# M460 register map
File version: 1.0
Registers are 32-bit, read-write, reset 0x0 unless marked. A register's access mark holds for its fields unless they carry their own. Offsets are from the block's base; [hi:lo] are bit positions; {n}, {i} and the like mark numbered series; 'fields as' and 'values as' point back to an identical list.

## CLK (part 1 of 2) — CLK Register Map
Base 0x40000200
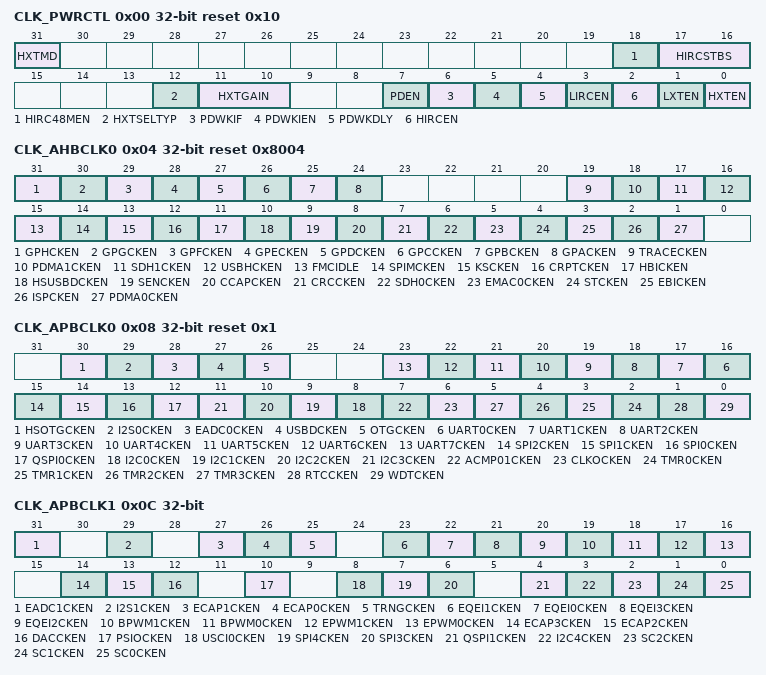
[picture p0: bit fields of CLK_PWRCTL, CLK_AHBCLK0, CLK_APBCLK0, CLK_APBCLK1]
0x00 CLK_PWRCTL reset 0x10 (reset mask 0xFFFF00F0) — System Power-down Control Register
  [31] HXTMD — HXT Mode Selection (Write Protect). Note 1: This bit is write protected. Refer to the SYS_REGCTL register. Note 2: When external clock mode enable, HXTSELTYP(CLK_PWRCTL[12]) must be set as GM type.
    0=HXT work as crystal mode. PF.2 and PF.3 are configured as external high speed crystal (HXT) pins; 1=HXT works as external clock mode. PF.3 is configured as external clock input pin
  [18] HIRC48MEN — HIRC48M Enable Bit (Write Protect). Note: This bit is write protected. Refer to the SYS_REGLCTL register.
    0=48 MHz internal high speed RC oscillator (HIRC48M) Disabled; 1=48 MHz internal high speed RC oscillator (HIRC48M) Enabled
  [17:16] HIRCSTBS — HIRC Stable Count Select (Write Protect). Note: These bits are write protected. Refer to the SYS_REGLCTL register.
    0=HIRC stable count is 64 clocks; 1=HIRC stable count is 24 clocks
  [12] HXTSELTYP — HXT Crystal Type Select Bit (Write Protect). Note: This bit is write protected. Refer to the SYS_REGLCTL register.
    0=Select INV type; 1=Select GM type
  [11:10] HXTGAIN — HXT Gain Control Bit (Write Protect). Gain control is used to enlarge the gain of crystal to make sure crystal work normally. Note: These bits are write protected. Refer to the SYS_REGLCTL register.
    0=HXT frequency is lower than from 8 MHz; 1=HXT frequency is from 8 MHz to 12 MHz; 2=HXT frequency is from 12 MHz to 16 MHz; 3=HXT frequency is higher than 16 MHz
  [7] PDEN — System Power-down Enable (Write Protect). When this bit is set to 1, Power-down mode is enabled and chip keeps active till the CPU sleep mode is also active and then the chip enters Power-down mode. When chip wakes up from Power-down mode, this bit is auto cleared. Users need to set this bit again for next Power-down. In Power-down mode, HXT and the HIRC will be disabled in this mode, but LXT and LIRC are not controlled by Power-down mode. In Power-down mode, the PLL, PLLFN and system clock are disabled, and ignored the clock source selection. The clocks of peripheral are not controlled by Power-down mode, if the peripheral clock source is from LXT or LIRC. Note 1: This bit is write protected. Refer to the SYS_REGLCTL register. Note 2: System tick interrupt TICKINT(SYS_CTRL[1]) has to be disabled before entering to Power-down mode, to avoid system tick interrupt may influence system not entering power-down mode and keep operation.
    0=Chip will not enter Power-down mode after CPU sleep command WFI; 1=Chip enters Power-down mode after CPU sleep command WFI
  [6] PDWKIF — Power-down Mode Wake-up Interrupt Status. Set by 'Power-down wake-up event', it indicates that resume from Power-down mode. The flag is set if any wake-up source occurred. Refer Power Modes and Wake-up Sources chapter. Note 1: Write 1 to clear the bit to 0. Note 2: This bit works only if PDWKIEN (CLK_PWRCTL[5]) set to 1.
  [5] PDWKIEN — Power-down Mode Wake-up Interrupt Enable Bit (Write Protect). Note 1: The interrupt will occur when both PDWKIF and PDWKIEN are high. Note 2: This bit is write protected. Refer to the SYS_REGLCTL register.
    0=Power-down mode wake-up interrupt Disabled; 1=Power-down mode wake-up interrupt Enabled
  [4] PDWKDLY — Enable the Wake-up Delay Counter (Write Protect). When the chip wakes up from Power-down mode, the clock control will delay certain clock cycles to wait system clock stable. The delayed clock cycle is 4096 clock cycles when chip works at 4~24 MHz external high speed crystal oscillator (HXT), and 64 or 24 clock cycles when chip works at 12 MHz internal high speed RC oscillator (HIRC). Note: This bit is write protected. Refer to the SYS_REGLCTL register.
    0=Clock cycles delay Disabled; 1=Clock cycles delay Enabled
  [3] LIRCEN — LIRC Enable Bit (Write Protect). Note: This bit is write protected. Refer to the SYS_REGLCTL register.
    0=10 kHz internal low speed RC oscillator (LIRC) Disabled; 1=10 kHz internal low speed RC oscillator (LIRC) Enabled
  [2] HIRCEN — HIRC Enable Bit (Write Protect). Note: This bit is write protected. Refer to the SYS_REGLCTL register.
    0=12 MHz internal high speed RC oscillator (HIRC) Disabled; 1=12 MHz internal high speed RC oscillator (HIRC) Enabled
  [1] LXTEN — LXT Enable Bit (Write Protect). Note: This bit is write protected. Refer to the SYS_REGLCTL register.
    0=32.768 kHz external low speed crystal (LXT) Disabled; 1=32.768 kHz external low speed crystal (LXT) Enabled
  [0] HXTEN — HXT Enable Bit (Write Protect). Note: This bit is write protected. Refer to the SYS_REGLCTL register.
    0=4~24 MHz external high speed crystal (HXT) Disabled; 1=4~24 MHz external high speed crystal (HXT) Enabled
0x04 CLK_AHBCLK0 reset 0x8004 — AHB Devices Clock Enable Control Register 0
  [31] GPHCKEN — GPIOH Clock Enable Bit
    0=GPIOH clock Disabled; 1=GPIOH clock Enabled
  [30] GPGCKEN — GPIOG Clock Enable Bit
    0=GPIOG clock Disabled; 1=GPIOG clock Enabled
  [29] GPFCKEN — GPIOF Clock Enable Bit
    0=GPIOF clock Disabled; 1=GPIOF clock Enabled
  [28] GPECKEN — GPIOE Clock Enable Bit
    0=GPIOE clock Disabled; 1=GPIOE clock Enabled
  [27] GPDCKEN — GPIOD Clock Enable Bit
    0=GPIOD clock Disabled; 1=GPIOD clock Enabled
  [26] GPCCKEN — GPIOC Clock Enable Bit
    0=GPIOC clock Disabled; 1=GPIOC clock Enabled
  [25] GPBCKEN — GPIOB Clock Enable Bit
    0=GPIOB clock Disabled; 1=GPIOB clock Enabled
  [24] GPACKEN — GPIOA Clock Enable Bit
    0=GPIOA clock Disabled; 1=GPIOA clock Enabled
  [19] TRACECKEN — TRACE Clock Enable Bit
    0=TRACE clock Disabled; 1=TRACE clock Enabled
  [18] PDMA1CKEN — PDMA1 Clock Enable Bit
    0=PDMA1 clock Disabled; 1=PDMA1 clock Enabled
  [17] SDH1CKEN — SDH1 Controller Clock Enable Bit
    0=SDH1 clock Disabled; 1=SDH1 clock Enabled
  [16] USBHCKEN — USB HOST Controller Clock Enable Bit
    0=USB HOST peripheral clock Disabled; 1=USB HOST peripheral clock Enabled
  [15] FMCIDLE — Flash Memory Controller Clock Enable Bit in IDLE Mode
    0=FMC clock Disabled when chip is under IDLE mode; 1=FMC clock Enabled when chip is under IDLE mode
  [14] SPIMCKEN — SPIM Controller Clock Enable Bit
    0=SPIM controller clock Disabled; 1=SPIM controller clock Enabled
  [13] KSCKEN — Key Store Clock Enable Bit
    0=Key Store clock Disabled; 1=Key Store clock Enabled
  [12] CRPTCKEN — Cryptographic Accelerator Clock Enable Bit
    0=Cryptographic Accelerator clock Disabled; 1=Cryptographic Accelerator clock Enabled
  [11] HBICKEN — HyperBus Interface Clock Enable Bit
    0=HBI clock Disabled; 1=HBI clock Enabled
  [10] HSUSBDCKEN — HSUSB Device Clock Enable Bit
    0=HSUSB device controller clock Disabled; 1=HSUSB device controller clock Enabled
  [9] SENCKEN — CCAP Sensor Clock Enable Control
    0=CCAP Sensor clock Disabled; 1=CCAP Sensor clock Enabled
  [8] CCAPCKEN — Camera Capture Interface Controller Clock Enable Control
    0=CCAP controller clock Disabled; 1=CCAP controller clock Enabled
  [7] CRCCKEN — CRC Generator Controller Clock Enable Bit
    0=CRC peripheral clock Disabled; 1=CRC peripheral clock Enabled
  [6] SDH0CKEN — SDH0 Controller Clock Enable Bit
    0=SDH0 clock Disabled; 1=SDH0 clock Enabled
  [5] EMAC0CKEN — EMAC0 Controller Clock Enable Bit
    0=EMAC0 controller clock Disabled; 1=EMAC0 controller clock Enabled
  [4] STCKEN — System Tick Clock Enable Bit
    0=System tick clock Disabled; 1=System tick clock Enabled
  [3] EBICKEN — EBI Controller Clock Enable Bit
    0=EBI peripheral clock Disabled; 1=EBI peripheral clock Enabled
  [2] ISPCKEN — Flash ISP Controller Clock Enable Bit
    0=Flash ISP peripheral clock Disabled; 1=Flash ISP peripheral clock Enabled
  [1] PDMA0CKEN — PDMA0 Controller Clock Enable Bit
    0=PDMA0 peripheral clock Disabled; 1=PDMA0 peripheral clock Enabled
0x08 CLK_APBCLK0 reset 0x1 — APB Devices Clock Enable Control Register 0
  [30] HSOTGCKEN — HSUSB OTG Clock Enable Bit
    0=HSUSB OTG clock Disabled; 1=HSUSB OTG clock Enabled
  [29] I2S0CKEN — I2S0 Clock Enable Bit
    0=I2S0 clock Disabled; 1=I2S0 clock Enabled
  [28] EADC0CKEN — EADC0 Clock Enable Bit
    0=EADC0 clock Disabled; 1=EADC0 clock Enabled
  [27] USBDCKEN — USB Device Clock Enable Bit
    0=USB device clock Disabled; 1=USB device clock Enabled
  [26] OTGCKEN — USB OTG Clock Enable Bit
    0=USB OTG clock Disabled; 1=USB OTG clock Enabled
  [n+16] UART{n}CKEN (n=0..7) — UART{n} Clock Enable Bit
    0=UART{n} clock Disabled; 1=UART{n} clock Enabled
  [15] SPI2CKEN — SPI2 Clock Enable Bit
    0=SPI2 clock Disabled; 1=SPI2 clock Enabled
  [14] SPI1CKEN — SPI1 Clock Enable Bit
    0=SPI1 clock Disabled; 1=SPI1 clock Enabled
  [13] SPI0CKEN — SPI0 Clock Enable Bit
    0=SPI0 clock Disabled; 1=SPI0 clock Enabled
  [12] QSPI0CKEN — QSPI0 Clock Enable Bit
    0=QSPI0 clock Disabled; 1=QSPI0 clock Enabled
  [n+8] I2C{n}CKEN (n=0..3) — I2C{n} Clock Enable Bit
    0=I2C{n} clock Disabled; 1=I2C{n} clock Enabled
  [7] ACMP01CKEN — Analog Comparator 0/1 Clock Enable Bit
    0=Analog comparator 0/1 clock Disabled; 1=Analog comparator 0/1 clock Enabled
  [6] CLKOCKEN — CLKO Clock Enable Bit
    0=CLKO clock Disabled; 1=CLKO clock Enabled
  [n+2] TMR{n}CKEN (n=0..3) — Timer{n} Clock Enable Bit
    0=Timer{n} clock Disabled; 1=Timer{n} clock Enabled
  [1] RTCCKEN — Real-time-clock APB Interface Clock Enable Bit. This bit is used to control the RTC APB clock only. The RTC peripheral clock source is selected from RTCCKSEL(RTC_LXTCTL[7]). It can be selected to 32.768 kHz external low speed crystal (LXT) or 10 kHz internal low speed RC oscillator (LIRC).
    0=RTC clock Disabled; 1=RTC clock Enabled
  [0] WDTCKEN — Watchdog Timer Clock Enable Bit (Write Protect). Note: This bit is write protected. Refer to the SYS_REGLCTL register.
    0=Watchdog timer clock Disabled; 1=Watchdog timer clock Enabled
0x0C CLK_APBCLK1 — APB Devices Clock Enable Control Register 1
  [31] EADC1CKEN — EADC1 Clock Enable Bit
    0=EADC1 clock Disabled; 1=EADC1 clock Enabled
  [29] I2S1CKEN — I2S1 Clock Enable Bit
    0=I2S1 clock Disabled; 1=I2S1 clock Enabled
  [27] ECAP1CKEN — ECAP1 Clock Enable Bit
    0=ECAP1 clock Disabled; 1=ECAP1 clock Enabled
  [26] ECAP0CKEN — ECAP0 Clock Enable Bit
    0=ECAP0 clock Disabled; 1=ECAP0 clock Enabled
  [25] TRNGCKEN — TRNG Clock Enable Bit
    0=TRNG clock Disabled; 1=TRNG clock Enabled
  [23] EQEI1CKEN — EQEI1 Clock Enable Bit
    0=EQEI1 clock Disabled; 1=EQEI1 clock Enabled
  [22] EQEI0CKEN — EQEI0 Clock Enable Bit
    0=EQEI0 clock Disabled; 1=EQEI0 clock Enabled
  [21] EQEI3CKEN — EQEI3 Clock Enable Bit
    0=QEI3 clock Disabled; 1=QEI3 clock Enabled
  [20] EQEI2CKEN — EQEI2 Clock Enable Bit
    0=EQEI2 clock Disabled; 1=EQEI2 clock Enabled
  [19] BPWM1CKEN — BPWM1 Clock Enable Bit
    0=BPWM1 clock Disabled; 1=BPWM1 clock Enabled
  [18] BPWM0CKEN — BPWM0 Clock Enable Bit
    0=BPWM0 clock Disabled; 1=BPWM0 clock Enabled
  [17] EPWM1CKEN — EPWM1 Clock Enable Bit
    0=EPWM1 clock Disabled; 1=EPWM1 clock Enabled
  [16] EPWM0CKEN — EPWM0 Clock Enable Bit
    0=EPWM0 clock Disabled; 1=EPWM0 clock Enabled
  [14] ECAP3CKEN — ECAP3 Clock Enable Bit
    0=ECAP3 clock Disabled; 1=ECAP3 clock Enabled
  [13] ECAP2CKEN — ECAP2 Clock Enable Bit
    0=ECAP2 clock Disabled; 1=ECAP2 clock Enabled
  [12] DACCKEN — DAC Clock Enable Bit
    0=DAC clock Disabled; 1=DAC clock Enabled
  [10] PSIOCKEN — PSIO Clock Enable Bit
    0=PSIO clock Disabled; 1=PSIO clock Enabled
  [8] USCI0CKEN — USCI0 Clock Enable Bit
    0=USCI0 clock Disabled; 1=USCI0 clock Enabled
  [7] SPI4CKEN — SPI4 Clock Enable Bit
    0=SPI4 clock Disabled; 1=SPI4 clock Enabled
  [6] SPI3CKEN — SPI3 Clock Enable Bit
    0=SPI3 clock Disabled; 1=SPI3 clock Enabled
  [4] QSPI1CKEN — QSPI1 Clock Enable Bit
    0=QSPI1 clock Disabled; 1=QSPI1 clock Enabled
  [3] I2C4CKEN — I2C4 Clock Enable Bit
    0=I2C4 clock Disabled; 1=I2C4 clock Enabled
  [2] SC2CKEN — SC2 Clock Enable Bit
    0=SC2 clock Disabled; 1=SC2 clock Enabled
  [1] SC1CKEN — SC1 Clock Enable Bit
    0=SC1 clock Disabled; 1=SC1 clock Enabled
  [0] SC0CKEN — SC0 Clock Enable Bit
    0=SC0 clock Disabled; 1=SC0 clock Enabled
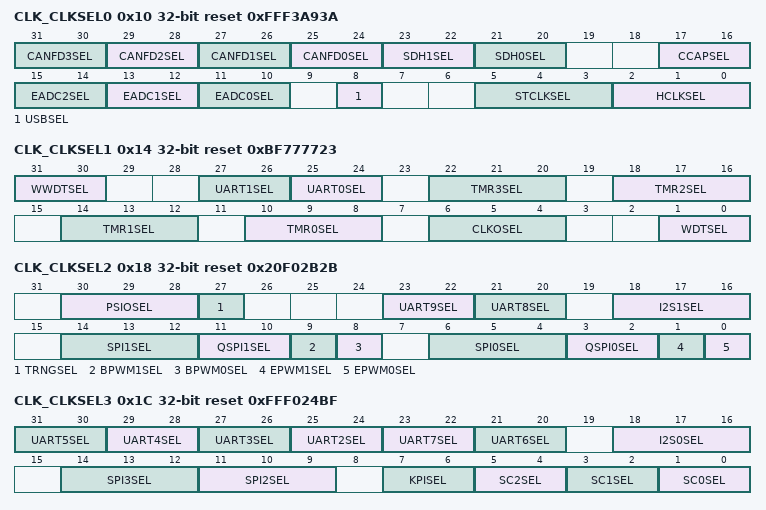
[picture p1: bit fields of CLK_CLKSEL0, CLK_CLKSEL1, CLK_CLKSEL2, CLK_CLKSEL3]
0x10 CLK_CLKSEL0 reset 0xFFF3A93A — Clock Source Select Control Register 0
  [2n+25:2n+24] CANFD{n}SEL (n=0..3) — CANFD{n} Clock Source Selection (Write Protect). Note: These bits are write protected. Refer to the SYS_REGLCTL register.
    0=Clock source from 4~24 MHz external high speed crystal oscillator (HXT); 1=Clock source from PLL/2 clock; 2=Clock source from HCLK; 3=Clock source from 12 MHz internal high speed RC oscillator (HIRC)
  [23:22] SDH1SEL — SDH1 Clock Source Selection (Write Protect). Note: These bits are write protected. Refer to the SYS_REGLCTL register.
    values as CANFD0SEL
  [21:20] SDH0SEL — SDH0 Clock Source Selection (Write Protect). Note: These bits are write protected. Refer to the SYS_REGLCTL register.
    values as CANFD0SEL
  [17:16] CCAPSEL — CCAP Sensor Clock Source Selection (Write Protect). Note: These bits are write protected. Refer to the SYS_REGLCTL register.
    0=Clock source from 4~24 MHz external high speed crystal oscillator (HXT); 1=Clock source from PLL/2; 2=Clock source from HCLK; 3=Clock source from 12 MHz internal high speed RC oscillator (HIRC)
  [15:14] EADC2SEL — EADC2 Clock Source Selection (Write Protect). Note: These bits are write protected. Refer to the SYS_REGLCTL register.
    0=Clock source from PLLFN/2; 1=Clock source from PLL/2; 2=Clock source from HCLK
  [13:12] EADC1SEL — EADC1 Clock Source Selection (Write Protect). Note: These bits are write protected. Refer to the SYS_REGLCTL register.
    values as EADC2SEL
  [11:10] EADC0SEL — EADC0 Clock Source Selection (Write Protect). Note: These bits are write protected. Refer to the SYS_REGLCTL register.
    values as EADC2SEL
  [8] USBSEL — USB Clock Source Selection (Write Protect). Note: This bit is write protected. Refer to the SYS_REGLCTL register.
    0=Clock source from 48 MHz internal high speed RC oscillator (HIRC48M); 1=Clock source from PLL/2
  [5:3] STCLKSEL — Cortex-M4 SysTick Clock Source Selection (Write Protect). Note 2: These bits are write protected. Refer to the SYS_REGLCTL register.
    0=Clock source from 4~24 MHz external high speed crystal oscillator (HXT); 1=Clock source from 32.768 kHz external low speed crystal oscillator (LXT); 2=Clock source from HXT/2; 3=Clock source from HCLK/2; 7=Clock source from HIRC/2
  [2:0] HCLKSEL — HCLK Clock Source Selection (Write Protect). Before clock switching, the related clock sources (both pre-select and new-select) must be turned on. Note: Theses bits are write protected. Refer to the SYS_REGLCTL register.
    0=Clock source from 4~24 MHz external high speed crystal oscillator (HXT); 1=Clock source from 32.768 kHz external low speed crystal oscillator (LXT); 2=Clock source from PLL; 3=Clock source from 10 kHz internal low speed RC oscillator (LIRC); 7=Clock source from 12 MHz internal high speed RC oscillator (HIRC)
0x14 CLK_CLKSEL1 reset 0xBF777723 — Clock Source Select Control Register 1
  [31:30] WWDTSEL — Window Watchdog Timer Clock Source Selection (Write Protect). Note: These bits are write protected. Refer to the SYS_REGLCTL register.
    2=Clock source from HCLK/2048; 3=Clock source from 10 kHz internal low speed RC oscillator (LIRC)
  [27:26] UART1SEL — UART1 Clock Source Selection
    0=Clock source from 4~24 MHz external high speed crystal oscillator (HXT); 1=Clock source from PLL/2; 2=Clock source from 32.768 kHz external low speed crystal oscillator (LXT); 3=Clock source from 12 MHz internal high speed RC oscillator (HIRC)
  [25:24] UART0SEL — UART0 Clock Source Selection
    values as UART1SEL
  [22:20] TMR3SEL — TIMER3 Clock Source Selection
    0=Clock source from 4~24 MHz external high speed crystal oscillator (HXT); 1=Clock source from 32.768 kHz external low speed crystal oscillator (LXT); 2=Clock source from PCLK1; 3=Clock source from external clock TM3 pin; 5=Clock source from 10 kHz internal low speed RC oscillator (LIRC); 7=Clock source from 12 MHz internal high speed RC oscillator (HIRC)
  [18:16] TMR2SEL — TIMER2 Clock Source Selection
    0=Clock source from 4~24 MHz external high speed crystal oscillator (HXT); 1=Clock source from 32.768 kHz external low speed crystal oscillator (LXT); 2=Clock source from PCLK1; 3=Clock source from external clock TM2 pin; 5=Clock source from 10 kHz internal low speed RC oscillator (LIRC); 7=Clock source from 12 MHz internal high speed RC oscillator (HIRC)
  [14:12] TMR1SEL — TIMER1 Clock Source Selection
    0=Clock source from 4~24 MHz external high speed crystal oscillator (HXT); 1=Clock source from 32.768 kHz external low speed crystal oscillator (LXT); 2=Clock source from PCLK0; 3=Clock source from external clock TM1 pin; 5=Clock source from 10 kHz internal low speed RC oscillator (LIRC); 7=Clock source from 12 MHz internal high speed RC oscillator (HIRC)
  [10:8] TMR0SEL — TIMER0 Clock Source Selection
    0=Clock source from 4~24 MHz external high speed crystal oscillator (HXT); 1=Clock source from 32.768 kHz external low speed crystal oscillator (LXT); 2=Clock source from PCLK0; 3=Clock source from external clock TM0 pin; 5=Clock source from 10 kHz internal low speed RC oscillator (LIRC); 7=Clock source from 12 MHz internal high speed RC oscillator (HIRC)
  [6:4] CLKOSEL — Clock Output Clock Source Selection (Write Protect). Note: These bits are write protected. Refer to the SYS_REGLCTL register.
    0=Clock source from 4~24 MHz external high speed crystal oscillator (HXT); 1=Clock source from 32.768 kHz external low speed crystal oscillator (LXT); 2=Clock source from HCLK; 3=Clock source from 12 MHz internal high speed RC oscillator (HIRC); 4=Clock source from 10 kHz internal low speed RC oscillator (LIRC); 5=Clock source from PLLFN/2; 6=Clock source from PLL/2
  [1:0] WDTSEL — Watchdog Timer Clock Source Selection (Write Protect). Note: These bits are write protected. Refer to the SYS_REGLCTL register.
    1=Clock source from 32.768 kHz external low speed crystal oscillator (LXT); 2=Clock source from HCLK/2048; 3=Clock source from 10 kHz internal low speed RC oscillator (LIRC)
0x18 CLK_CLKSEL2 reset 0x20F02B2B — Clock Source Select Control Register 2
  [30:28] PSIOSEL — PSIO Clock Source Selection
    0=Clock source from 4~24 MHz external high speed crystal oscillator (HXT); 1=Clock source from 32.768 kHz external low speed crystal oscillator (LXT); 2=Clock source from PCLK1; 3=Clock source from PLL/2; 4=Clock source from 10 kHz internal low speed RC oscillator (LIRC); 5=Clock source from 12 MHz internal high speed RC oscillator (HIRC)
  [27] TRNGSEL — TRNG Clock Source Selection
    0=Clock source from 32.768 kHz external low speed crystal oscillator (LXT); 1=Clock source from 10 kHz internal low speed RC oscillator (LIRC)
  [23:22] UART9SEL — UART9 Clock Source Selection
    values as CLK_CLKSEL1.UART1SEL
  [21:20] UART8SEL — UART8 Clock Source Selection
    values as CLK_CLKSEL1.UART1SEL
  [18:16] I2S1SEL — I2S1 Clock Source Selection
    0=Clock source from 4~24 MHz external high speed crystal oscillator (HXT); 1=Clock source from PLL/2; 2=Clock source from PCLK1; 3=Clock source from 12 MHz internal high speed RC oscillator (HIRC); 4=Clock source from 48 MHz internal high speed RC oscillator (HIRC48M); 5=Clock source from PLLFN/2
  [14:12] SPI1SEL — SPI1 Clock Source Selection
    0=Clock source from 4~24 MHz external high speed crystal oscillator (HXT); 1=Clock source from PLL/2; 2=Clock source from PCLK0; 3=Clock source from 12 MHz internal high speed RC oscillator (HIRC); 4=Clock source from 48 MHz internal high speed RC oscillator (HIRC48M); 5=Clock source from PLLFN/2
  [11:10] QSPI1SEL — QSPI1 Clock Source Selection
    0=Clock source from 4~24 MHz external high speed crystal oscillator (HXT); 1=Clock source from PLL/2; 2=Clock source from PCLK1; 3=Clock source from 12 MHz internal high speed RC oscillator (HIRC)
  [9] BPWM1SEL — BPWM1 Clock Source Selection. The peripheral clock source of BPWM1 is defined by BPWM1SEL.
    0=Clock source from HCLK; 1=Clock source from PCLK1
  [8] BPWM0SEL — BPWM0 Clock Source Selection. The peripheral clock source of BPWM0 is defined by BPWM0SEL.
    0=Clock source from HCLK; 1=Clock source from PCLK0
  [6:4] SPI0SEL — SPI0 Clock Source Selection
    values as I2S1SEL
  [3:2] QSPI0SEL — QSPI0 Clock Source Selection
    0=Clock source from 4~24 MHz external high speed crystal oscillator (HXT); 1=Clock source from PLL/2; 2=Clock source from PCLK0; 3=Clock source from 12 MHz internal high speed RC oscillator (HIRC)
  [1] EPWM1SEL — EPWM1 Clock Source Selection. The peripheral clock source of EPWM1 is defined by EPWM1SEL.
    0=Clock source from HCLK; 1=Clock source from PCLK1
  [0] EPWM0SEL — EPWM0 Clock Source Selection. The peripheral clock source of EPWM0 is defined by EPWM0SEL.
    0=Clock source from HCLK; 1=Clock source from PCLK0
0x1C CLK_CLKSEL3 reset 0xFFF024BF — Clock Source Select Control Register 3
  [2n+21:2n+20] UART{n}SEL (n=2..5) — UART{n} Clock Source Selection
    values as CLK_CLKSEL1.UART1SEL
  [23:22] UART7SEL — UART7 Clock Source Selection
    values as CLK_CLKSEL1.UART1SEL
  [21:20] UART6SEL — UART6 Clock Source Selection
    values as CLK_CLKSEL1.UART1SEL
  [18:16] I2S0SEL — I2S0 Clock Source Selection
    values as CLK_CLKSEL2.SPI1SEL
  [14:12] SPI3SEL — SPI3 Clock Source Selection
    values as CLK_CLKSEL2.SPI1SEL
  [11:9] SPI2SEL — SPI2 Clock Source Selection
    values as CLK_CLKSEL2.I2S1SEL
  [7:6] KPISEL — KPI Clock Source Selection
    0=Clock source from 4~24 MHz external high speed crystal oscillator (HXT); 1=Clock source from 10 kHz internal low speed RC oscillator (LIRC); 2=Clock source from 12 MHz internal high speed RC oscillator (HIRC)
  [5:4] SC2SEL — SC2 Clock Source Selection
    values as CLK_CLKSEL2.QSPI0SEL
  [3:2] SC1SEL — SC0 Clock Source Selection
    values as CLK_CLKSEL2.QSPI1SEL
  [1:0] SC0SEL — SC0 Clock Source Selection
    values as CLK_CLKSEL2.QSPI0SEL
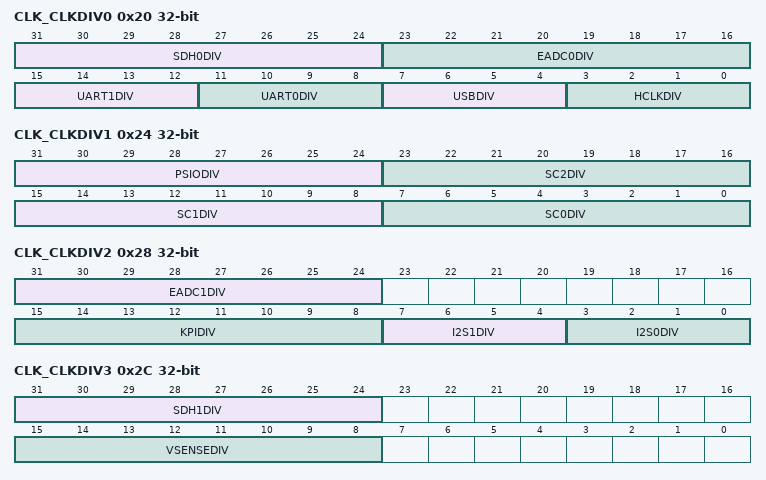
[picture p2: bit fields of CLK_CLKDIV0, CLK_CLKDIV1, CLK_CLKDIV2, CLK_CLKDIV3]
0x20 CLK_CLKDIV0 — Clock Divider Number Register 0
  [31:24] SDH0DIV — SDH0 Clock Divide Number from SDH0 Clock Source
  [23:16] EADC0DIV — EADC0 Clock Divide Number from EADC0 Clock Source
  [15:12] UART1DIV — UART1 Clock Divide Number from UART1 Clock Source
  [11:8] UART0DIV — UART0 Clock Divide Number from UART0 Clock Source
  [7:4] USBDIV — USB Clock Divide Number from PLL/2 Clock
  [3:0] HCLKDIV — HCLK Clock Divide Number from HCLK Clock Source
0x24 CLK_CLKDIV1 — Clock Divider Number Register 1
  [31:24] PSIODIV — PSIO Clock Divide Number from PSIO Clock Source
  [23:16] SC2DIV — SC2 Clock Divide Number from SC2 Clock Source
  [15:8] SC1DIV — SC1 Clock Divide Number from SC1 Clock Source
  [7:0] SC0DIV — SC0 Clock Divide Number from SC0 Clock Source
0x28 CLK_CLKDIV2 — Clock Divider Number Register 2
  [31:24] EADC1DIV — EADC1 Clock Divide Number from EADC1 Clock Source
  [15:8] KPIDIV — KPI Clock Divide Number from KPI Clock Source
  [7:4] I2S1DIV — I2S1 Clock Divide Number from I2S1 Clock Source
  [3:0] I2S0DIV — I2S0 Clock Divide Number from I2S0 Clock Source
0x2C CLK_CLKDIV3 — Clock Divider Number Register 3
  [31:24] SDH1DIV — SDH1 Clock Divide Number from SDH1 Clock Source
  [15:8] VSENSEDIV — Video Pixel Clock Divide Number from CCAP Sensor Clock Source
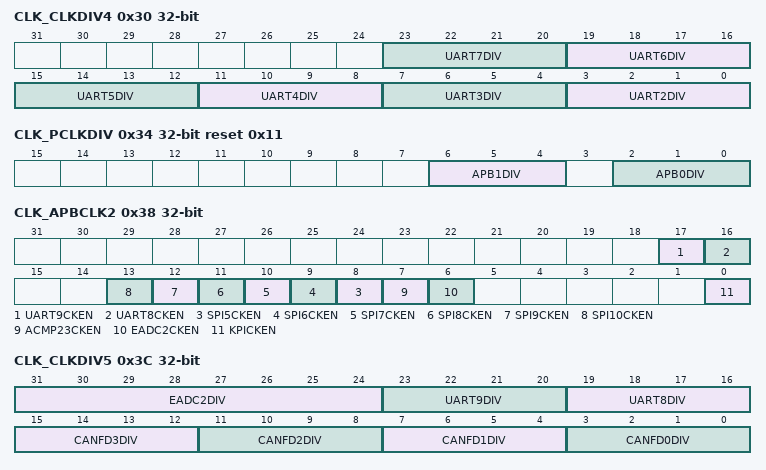
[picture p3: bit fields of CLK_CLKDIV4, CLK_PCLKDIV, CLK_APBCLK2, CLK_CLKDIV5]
0x30 CLK_CLKDIV4 — Clock Divider Number Register 4
  [4n-5:4n-8] UART{n}DIV (n=2..7) — UART{n} Clock Divide Number from UART{n} Clock Source
0x34 CLK_PCLKDIV reset 0x11 — APB Clock Divider Register
  [6:4] APB1DIV — APB1 Clock Divider. APB1 clock can be divided from HCLK.
    0=PCLK1 frequency is HCLK; 1=PCLK1 frequency is HCLK/2; 2=PCLK1 frequency is HCLK/4; 3=PCLK1 frequency is HCLK/8; 4=PCLK1 frequency is HCLK/16
  [2:0] APB0DIV — APB0 Clock Divider. APB0 clock can be divided from HCLK.
    0=PCLK0 frequency is HCLK; 1=PCLK0 frequency is HCLK/2; 2=PCLK0 frequency is HCLK/4; 3=PCLK0 frequency is HCLK/8; 4=PCLK0 frequency is HCLK/16
0x38 CLK_APBCLK2 — APB Devices Clock Enable Control Register 2
  [17] UART9CKEN — UART9 Clock Enable Bit
    0=UART9 clock Disabled; 1=UART9 clock Enabled
  [16] UART8CKEN — UART8 Clock Enable Bit
    0=UART8 clock Disabled; 1=UART8 clock Enabled
  [n+3] SPI{n}CKEN (n=5..10) — SPI{n} Clock Enable Bit
    0=SPI{n} clock Disabled; 1=SPI{n} clock Enabled
  [7] ACMP23CKEN — Analog Comparator 2/3 Clock Enable Bit
    0=Analog comparator 2/3 clock Disabled; 1=Analog comparator 2/3 clock Enabled
  [6] EADC2CKEN — EADC2 Clock Enable Bit
    0=EADC2 clock Disabled; 1=EADC2 clock Enabled
  [0] KPICKEN — KPI Clock Enable Bit
    0=KPI clock Disabled; 1=KPI clock Enabled
0x3C CLK_CLKDIV5 — Clock Divider Number Register 5
  [31:24] EADC2DIV — EADC2 Clock Divide Number from EADC2 Clock Source
  [23:20] UART9DIV — UART9 Clock Divide Number from UART9 Clock Source
  [19:16] UART8DIV — UART8 Clock Divide Number from UART8 Clock Source
  [4n+3:4n] CANFD{n}DIV (n=0..3) — CANFD{n} Clock Divide Number from CANFD{n} Clock Source
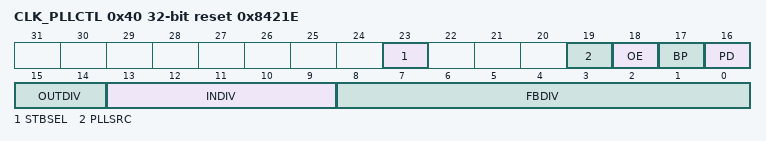
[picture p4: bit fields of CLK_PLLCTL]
0x40 CLK_PLLCTL reset 0x8421E — PLL Control Register
  [23] STBSEL — PLL Stable Counter Selection (Write Protect). Note: This bit is write protected. Refer to the SYS_REGLCTL register.
    0=PLL stable time is 1200 PLL source clock (suitable for source clock equal to or less than 12 MHz); 1=PLL stable time is 2400 PLL source clock (suitable for source clock larger than 12 MHz)
  [19] PLLSRC — PLL Source Clock Selection (Write Protect). Note: This bit is write protected. Refer to the SYS_REGLCTL register.
    0=PLL source clock from 4~24 MHz external high-speed crystal oscillator (HXT); 1=PLL source clock from 12 MHz internal high-speed oscillator (HIRC)
  [18] OE — PLL FOUT Enable Control (Write Protect). Note: This bit is write protected. Refer to the SYS_REGLCTL register.
    0=PLL FOUT Enabled; 1=PLL FOUT is fixed low
  [17] BP — PLL Bypass Control (Write Protect). Note: This bit is write protected. Refer to the SYS_REGLCTL register.
    0=PLL is in normal mode (default); 1=PLL clock output is same as PLL input clock FIN
  [16] PD — Power-down Mode (Write Protect). If set the PDEN bit to 1 in CLK_PWRCTL register, the PLL will enter Power-down mode, too. Note: This bit is write protected. Refer to the SYS_REGLCTL register.
    0=PLL is in normal mode; 1=PLL is in Power-down mode (default)
  [15:14] OUTDIV — PLL Output Divider Control (Write Protect). Refer to the formulas below the table. Note: These bits are write protected. Refer to the SYS_REGLCTL register.
  [13:9] INDIV — PLL Input Divider Control (Write Protect). Refer to the formulas below the table. Note: These bits are write protected. Refer to the SYS_REGLCTL register.
  [8:0] FBDIV — PLL Feedback Divider Control (Write Protect). Refer to the formulas below the table. Note: These bits are write protected. Refer to the SYS_REGLCTL register.
